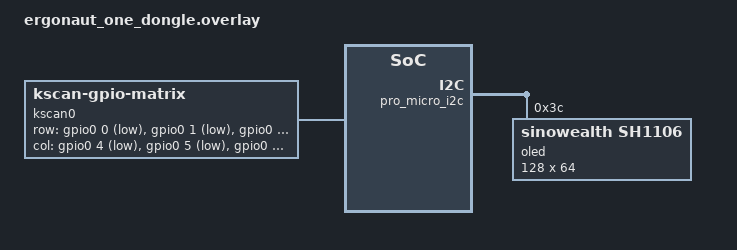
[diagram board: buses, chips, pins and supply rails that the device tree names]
/*
 * Copyright (c) 2020 The ZMK Contributors
 *
 * SPDX-License-Identifier: MIT
 */

#include "ergonaut_one_nice.dtsi"

/ {
    chosen {
        zmk,physical-layout = &ergonaut_physical_layout;        
    };
    kscan0: kscan {
        compatible = "zmk,kscan-gpio-matrix";
        row-gpios = <&gpio0 0 GPIO_ACTIVE_LOW>, <&gpio0 1 GPIO_ACTIVE_LOW>, <&gpio0 2 GPIO_ACTIVE_LOW>, <&gpio0 3 GPIO_ACTIVE_LOW>;
        col-gpios = <&gpio0 4 GPIO_ACTIVE_LOW>, <&gpio0 5 GPIO_ACTIVE_LOW>, <&gpio0 6 GPIO_ACTIVE_LOW>, <&gpio0 7 GPIO_ACTIVE_LOW>, <&gpio0 8 GPIO_ACTIVE_LOW>, <&gpio0 9 GPIO_ACTIVE_LOW>;
        diode-direction = "col2row";
    };

    ergonaut_physical_layout: physical_layout {
        compatible = "zmk,physical-layout";
        display-name = "Ergonaut";
        kscan = <&kscan0>;
        transform = <&default_transform>;
    };
};

&pro_micro_i2c {   
    status = "okay";

    oled: ssd1306@3c {
        compatible = "sinowealth,sh1106";
        reg = <0x3c>;
        width = <128>;
        height = <64>;
        segment-offset = <2>;
        page-offset = <0>;
        display-offset = <0>;
        multiplex-ratio = <63>;
        prechargep = <0x22>;
        inversion-on;
    };
};
